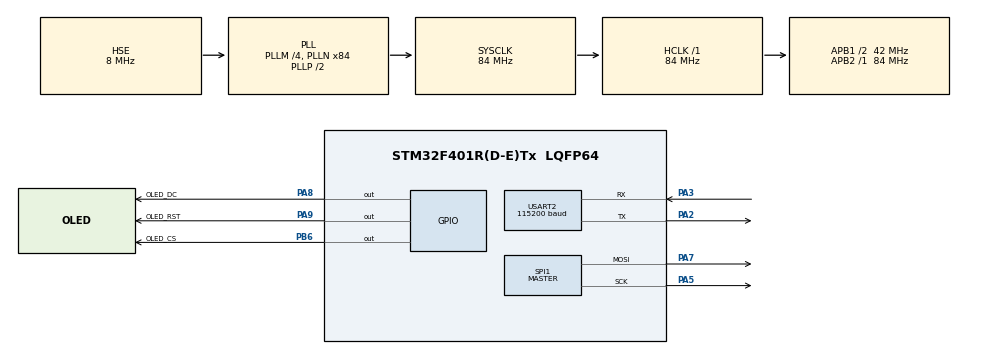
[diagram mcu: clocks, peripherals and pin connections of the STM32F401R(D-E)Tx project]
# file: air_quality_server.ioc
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FREERTOS.Tasks01=defaultTask,24,128,StartDefaultTask,Default,NULL,Dynamic,NULL,NULL
FREERTOS.configTOTAL_HEAP_SIZE=16384
FREERTOS.configUSE_TIMERS=1
Mcu.Family=STM32F4
Mcu.Name=STM32F401R(D-E)Tx
Mcu.Package=LQFP64
NVIC.PriorityGroup=NVIC_PRIORITYGROUP_4
NVIC.TIM1_UP_TIM10_IRQn=true\:15\:0\:false\:false\:true\:false\:false\:true\:true
NVIC.TimeBase=TIM1_UP_TIM10_IRQn
NVIC.TimeBaseIP=TIM1
NVIC.USART2_IRQn=true\:5\:0\:false\:false\:true\:true\:true\:true\:true
PA2.Mode=Asynchronous
PA2.Signal=USART2_TX
PA3.Mode=Asynchronous
PA3.Signal=USART2_RX
PA5.Mode=TX_Only_Simplex_Unidirect_Master
PA5.Signal=SPI1_SCK
PA7.Mode=TX_Only_Simplex_Unidirect_Master
PA7.Signal=SPI1_MOSI
PA8.GPIO_Label=OLED_DC
PA8.Signal=GPIO_Output
PA9.GPIO_Label=OLED_RST
PA9.Signal=GPIO_Output
PB6.GPIO_Label=OLED_CS
PB6.Signal=GPIO_Output
PH0\ -\ OSC_IN.Mode=HSE-External-Oscillator
PH0\ -\ OSC_IN.Signal=RCC_OSC_IN
PH1\ -\ OSC_OUT.Mode=HSE-External-Oscillator
PH1\ -\ OSC_OUT.Signal=RCC_OSC_OUT
ProjectManager.HeapSize=0x200
ProjectManager.StackSize=0x400
ProjectManager.TargetToolchain=CMake
RCC.48MHZClocksFreq_Value=42000000
RCC.AHBFreq_Value=84000000
RCC.APB1CLKDivider=RCC_HCLK_DIV2
RCC.APB1Freq_Value=42000000
RCC.APB1TimFreq_Value=84000000
RCC.APB2Freq_Value=84000000
RCC.APB2TimFreq_Value=84000000
RCC.CortexFreq_Value=84000000
RCC.HCLKFreq_Value=84000000
RCC.HSE_VALUE=8000000
RCC.HSI_VALUE=16000000
RCC.LSE_VALUE=32768
RCC.PLLM=4
RCC.PLLN=84
RCC.PLLP=RCC_PLLP_DIV2
RCC.PLLSourceVirtual=RCC_PLLSOURCE_HSE
RCC.SYSCLKFreq_VALUE=84000000
RCC.SYSCLKSource=RCC_SYSCLKSOURCE_PLLCLK
RCC.VCOOutputFreq_Value=168000000
SPI1.BaudRatePrescaler=SPI_BAUDRATEPRESCALER_8
SPI1.CLKPhase=SPI_PHASE_1EDGE
SPI1.CLKPolarity=SPI_POLARITY_LOW
SPI1.DataSize=SPI_DATASIZE_8BIT
SPI1.Direction=SPI_DIRECTION_2LINES
SPI1.FirstBit=SPI_FIRSTBIT_MSB
SPI1.Mode=SPI_MODE_MASTER
SPI1.VirtualType=VM_MASTER
USART2.BaudRate=115200
USART2.VirtualMode=VM_ASYNC
USART2.WordLength=WORDLENGTH_8B
VP_FREERTOS_VS_CMSIS_V2.Mode=CMSIS_V2
VP_SYS_VS_tim1.Mode=TIM1
board=custom

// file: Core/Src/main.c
/* USER CODE BEGIN Header */
/**
  ******************************************************************************
  * @file           : main.c
  * @brief          : Main program body
  ******************************************************************************
  * @attention
  *
  * Copyright (c) 2026 STMicroelectronics.
  * All rights reserved.
  *
  * This software is licensed under terms that can be found in the LICENSE file
  * in the root directory of this software component.
  * If no LICENSE file comes with this software, it is provided AS-IS.
  *
  ******************************************************************************
  */
/* USER CODE END Header */
#include "main.h"
#include "cmsis_os.h"

/* USER CODE BEGIN Includes */
#include "app/main.h"
/* USER CODE END Includes */

SPI_HandleTypeDef hspi1;

UART_HandleTypeDef huart2;

/* Definitions for defaultTask */
osThreadId_t defaultTaskHandle;
const osThreadAttr_t defaultTask_attributes = {
  .name = "defaultTask",
  .stack_size = 128 * 4,
  .priority = (osPriority_t) osPriorityNormal,
};

void SystemClock_Config(void);
static void MX_GPIO_Init(void);
static void MX_SPI1_Init(void);
static void MX_USART2_UART_Init(void);
void StartDefaultTask(void *argument);

int main(void)
{

  /* MCU Configuration--------------------------------------------------------*/

  /* Reset of all peripherals, Initializes the Flash interface and the Systick. */
  HAL_Init();

  /* Configure the system clock */
  SystemClock_Config();

  /* Initialize all configured peripherals */
  MX_GPIO_Init();
  MX_SPI1_Init();
  MX_USART2_UART_Init();

  /* Init scheduler */
  osKernelInitialize();

  /* Create the thread(s) */
  /* creation of defaultTask */
  defaultTaskHandle = osThreadNew(StartDefaultTask, NULL, &defaultTask_attributes);

  /* Start scheduler */
  osKernelStart();

  /* We should never get here as control is now taken by the scheduler */

  /* Infinite loop */
  while (1)
  {

  }
}

void SystemClock_Config(void)
{
  RCC_OscInitTypeDef RCC_OscInitStruct = {0};
  RCC_ClkInitTypeDef RCC_ClkInitStruct = {0};

  /** Configure the main internal regulator output voltage
  */
  __HAL_RCC_PWR_CLK_ENABLE();
  __HAL_PWR_VOLTAGESCALING_CONFIG(PWR_REGULATOR_VOLTAGE_SCALE2);

  /** Initializes the RCC Oscillators according to the specified parameters
  * in the RCC_OscInitTypeDef structure.
  */
  RCC_OscInitStruct.OscillatorType = RCC_OSCILLATORTYPE_HSE;
  RCC_OscInitStruct.HSEState = RCC_HSE_ON;
  RCC_OscInitStruct.PLL.PLLState = RCC_PLL_ON;
  RCC_OscInitStruct.PLL.PLLSource = RCC_PLLSOURCE_HSE;
  RCC_OscInitStruct.PLL.PLLM = 4;
  RCC_OscInitStruct.PLL.PLLN = 84;
  RCC_OscInitStruct.PLL.PLLP = RCC_PLLP_DIV2;
  RCC_OscInitStruct.PLL.PLLQ = 4;
  if (HAL_RCC_OscConfig(&RCC_OscInitStruct) != HAL_OK)
  {
    Error_Handler();
  }

  /** Initializes the CPU, AHB and APB buses clocks
  */
  RCC_ClkInitStruct.ClockType = RCC_CLOCKTYPE_HCLK|RCC_CLOCKTYPE_SYSCLK
                              |RCC_CLOCKTYPE_PCLK1|RCC_CLOCKTYPE_PCLK2;
  RCC_ClkInitStruct.SYSCLKSource = RCC_SYSCLKSOURCE_PLLCLK;
  RCC_ClkInitStruct.AHBCLKDivider = RCC_SYSCLK_DIV1;
  RCC_ClkInitStruct.APB1CLKDivider = RCC_HCLK_DIV2;
  RCC_ClkInitStruct.APB2CLKDivider = RCC_HCLK_DIV1;

  if (HAL_RCC_ClockConfig(&RCC_ClkInitStruct, FLASH_LATENCY_2) != HAL_OK)
  {
    Error_Handler();
  }
}

static void MX_SPI1_Init(void)
{

  /* SPI1 parameter configuration*/
  hspi1.Instance = SPI1;
  hspi1.Init.Mode = SPI_MODE_MASTER;
  hspi1.Init.Direction = SPI_DIRECTION_2LINES;
  hspi1.Init.DataSize = SPI_DATASIZE_8BIT;
  hspi1.Init.CLKPolarity = SPI_POLARITY_LOW;
  hspi1.Init.CLKPhase = SPI_PHASE_1EDGE;
  hspi1.Init.NSS = SPI_NSS_SOFT;
  hspi1.Init.BaudRatePrescaler = SPI_BAUDRATEPRESCALER_8;
  hspi1.Init.FirstBit = SPI_FIRSTBIT_MSB;
  hspi1.Init.TIMode = SPI_TIMODE_DISABLE;
  hspi1.Init.CRCCalculation = SPI_CRCCALCULATION_DISABLE;
  hspi1.Init.CRCPolynomial = 10;
  if (HAL_SPI_Init(&hspi1) != HAL_OK)
  {
    Error_Handler();
  }

}

static void MX_USART2_UART_Init(void)
{

  huart2.Instance = USART2;
  huart2.Init.BaudRate = 115200;
  huart2.Init.WordLength = UART_WORDLENGTH_8B;
  huart2.Init.StopBits = UART_STOPBITS_1;
  huart2.Init.Parity = UART_PARITY_NONE;
  huart2.Init.Mode = UART_MODE_TX_RX;
  huart2.Init.HwFlowCtl = UART_HWCONTROL_NONE;
  huart2.Init.OverSampling = UART_OVERSAMPLING_16;
  if (HAL_UART_Init(&huart2) != HAL_OK)
  {
    Error_Handler();
  }

}

static void MX_GPIO_Init(void)
{
  GPIO_InitTypeDef GPIO_InitStruct = {0};

  /* GPIO Ports Clock Enable */
  __HAL_RCC_GPIOH_CLK_ENABLE();
  __HAL_RCC_GPIOA_CLK_ENABLE();
  __HAL_RCC_GPIOB_CLK_ENABLE();

  /*Configure GPIO pin Output Level */
  HAL_GPIO_WritePin(GPIOA, OLED_DC_Pin|OLED_RST_Pin, GPIO_PIN_RESET);

  /*Configure GPIO pin Output Level */
  HAL_GPIO_WritePin(OLED_CS_GPIO_Port, OLED_CS_Pin, GPIO_PIN_RESET);

  /*Configure GPIO pins : OLED_DC_Pin OLED_RST_Pin */
  GPIO_InitStruct.Pin = OLED_DC_Pin|OLED_RST_Pin;
  GPIO_InitStruct.Mode = GPIO_MODE_OUTPUT_PP;
  GPIO_InitStruct.Pull = GPIO_NOPULL;
  GPIO_InitStruct.Speed = GPIO_SPEED_FREQ_LOW;
  HAL_GPIO_Init(GPIOA, &GPIO_InitStruct);

  /*Configure GPIO pin : OLED_CS_Pin */
  GPIO_InitStruct.Pin = OLED_CS_Pin;
  GPIO_InitStruct.Mode = GPIO_MODE_OUTPUT_PP;
  GPIO_InitStruct.Pull = GPIO_NOPULL;
  GPIO_InitStruct.Speed = GPIO_SPEED_FREQ_LOW;
  HAL_GPIO_Init(OLED_CS_GPIO_Port, &GPIO_InitStruct);

}

void StartDefaultTask(void *argument)
{
  /* USER CODE BEGIN 5 */
  app_main();
  /* Not reached — app_main terminates this thread after creating tasks */
  /* USER CODE END 5 */
}

void HAL_TIM_PeriodElapsedCallback(TIM_HandleTypeDef *htim)
{
  if (htim->Instance == TIM1)
  {
    HAL_IncTick();
  }
}

void Error_Handler(void)
{
  __disable_irq();
  while (1)
  {
  }
}
